# MATHACL_1.0 register map
Vendor: Texas Instruments
Peripheral module from a debugger description file (folder mspm0g1x0x_g3x0x).
Registers are 32-bit, read-write, no defined reset value unless marked. A register's access mark holds for its fields unless they carry their own. Offsets are as the file gives them; lines under a group give offsets from that group; [hi:lo] are bit positions; {n}, {i} and the like mark numbered series; 'fields as' and 'values as' point back to an identical list; <NAME> marks a mode.

## MATHACL
0x800 MATHACL_GPRCM group
  0x00 MATHACL_PWREN — Power enable
    [0] ENABLE — Enable the power
      0=DISABLE (Disable Power); 1=ENABLE (Enable Power)
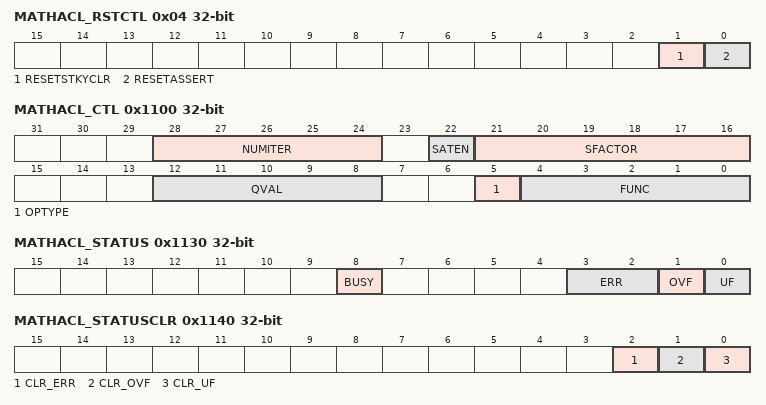
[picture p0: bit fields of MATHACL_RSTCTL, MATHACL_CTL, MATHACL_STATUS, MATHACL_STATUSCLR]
  0x04 MATHACL_RSTCTL — Reset Control
    [1] RESETSTKYCLR — Clear the RESETSTKY bit in the STAT register
      0=NOP (Writing 0 has no effect); 1=CLR (Clear reset sticky bit)
    [0] RESETASSERT — Assert reset to the peripheral
      0=NOP (Writing 0 has no effect); 1=ASSERT (Assert reset)
  0x14 MATHACL_STAT ro — Status Register
    [16] RESETSTKY — This bit indicates, if the peripheral was reset, since this bit was cleared by RESETSTKYCLR in the RSTCTL register
      0=NORES (The peripheral has not been reset since this bit was last cleared by RESETSTKYCLR in the RSTCTL register); 1=RESET (The peripheral was reset since the last bit clear)
0x1100 MATHACL_CTL — Control Register
  [28:24] NUMITER — Number of iterations, applicable if the function does the computations iteratively, for example sine/cosine/atan2/sqrt. Note: A value of 0 is interpreted as 31.
  [22] SATEN — Saturation enable This bit is shared among DIV, SQUARE32, MPY32, MAC and SAC functions. When enabled, it will make the result to saturate to maximum value in case of an overflow event When disabled, the result will overflow to an unknown value.
    0=DISABLE (Saturation is disabled); 1=ENABLE (Saturation is enabled)
  [21:16] SFACTOR — Scaling factor. In case of SQRT function, the input operand needs to be in a range. If not it has to be scaled to 2^(+/-n). This field should be written with the value 'n'.
  [12:8] QVAL — Indicates the fractional bits in the operands, ranges from 0 to 31. Applicable to DIV function.
    {v}=Q{v} (Q{v} operands) (v=0..31)
  [5] OPTYPE — Operand type, could signed or unsigned. applicable to DIV function.
    0=UNSIGNED (Unsigned operands); 1=SIGNED (Signed operands.)
  [4:0] FUNC — ULP_ADCHP Enable Conversions.
    0=NOP (No operation); 1=SINCOS (Sine and Cosine operation); 2=ATAN2 (Arc tangent with x and y values as operands.); 4=DIV (Divide, the operands are numerator, denominator, and the divide type. Result is the quotient and reminder.); 5=SQRT (Do square root. Operand is the number whoose square root needs to be computed. The number if outside the range needs to be scaled up down by 2 power 2n to bring it with in the range.); 6=MPY32 (32-bit Multiply Result); 7=SQUARE32 (32-bit square result); 8=MPY64 (64-bit multiply result); 9=SQUARE64 (64-bit multiply result); 10=MAC (Multiply and accumulate operation); 11=SAC (Square and accumulate operation)
0x1118 MATHACL_OP2 access not given — Operand 2 register.
0x111C MATHACL_OP1 access not given — Operand 1 register.
0x1120 MATHACL_RES1 access not given — Result 1 register.
0x1124 MATHACL_RES2 access not given — Result 2 register.
0x1130 MATHACL_STATUS ro — Status Register
  [8] BUSY — MATHACL busy bit.
    0=DONE (Compute has completed.); 1=NOTDONE (Compute ongoing)
  [3:2] ERR — Incorrect inputs/outputs.
    0=NOERROR (No Error in computation.); 1=DIVBY0 (DIVBY0 error)
  [1] OVF — Overflow bit for MPY32, SQUARE32, DIV, MAC, and SAC functions This bit will be set on overflow and will retain its value until cleared by writing 1 into CLR.CLR_OVF
    0=NO_OVERFLOW (No overflow error.); 0=OVERFLOW (Overflow error.)
  [0] UF — Underflow Flag
    0=NO_UNDERFLOW (No undreflow error.); 1=UNDERFLOW (Underflow error.)
0x1140 MATHACL_STATUSCLR — Status flag clear register
  [2] CLR_ERR — Write 1 to this bit to clear STATUS.ERR field
    0=NO_EFFECT (Writing 0 has no effect); 1=CLR (Clear STATUS.ERR)
  [1] CLR_OVF — Write 1 to this bit to clear STATUS.OVF bit
    0=NO_EFFECT (Writing 0 has no effect); 1=CLR (Clear STATUS.OVF)
  [0] CLR_UF — Write 1 to this bit to clear STATUS.UF bit
    0=NO_EFFECT (Writing 0 has no effect); 1=CLR (Clear STATUS.UF)
